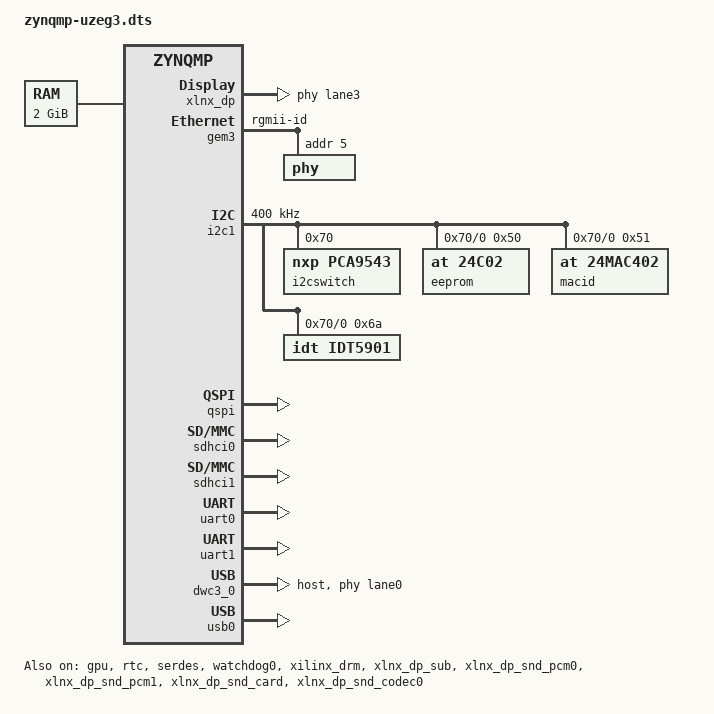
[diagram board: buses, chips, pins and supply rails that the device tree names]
/*
 * CAUTION: This file is automatically generated by Xilinx.
 * Version:
 * Today is: Wed Mar 15 10:40:02 2017
*/


/dts-v1/;
/include/ "zynqmp.dtsi"
/include/ "zynqmp-clk.dtsi"


/ {
	chosen {
		bootargs = "console=ttyPS0,115200";
	};
	aliases {
		ethernet0 = &gem3;
		serial0 = &uart0;
		serial1 = &uart1;
		spi0 = &qspi;
	};
	memory {
		device_type = "memory";
		reg = <0x0 0x0 0x0 0x80000000>;
	};
	cpus {
	};
};
&lpd_dma_chan1 {
	status = "okay";
};
&lpd_dma_chan2 {
	status = "okay";
};
&lpd_dma_chan3 {
	status = "okay";
};
&lpd_dma_chan4 {
	status = "okay";
};
&lpd_dma_chan5 {
	status = "okay";
};
&lpd_dma_chan6 {
	status = "okay";
};
&lpd_dma_chan7 {
	status = "okay";
};
&lpd_dma_chan8 {
	status = "okay";
};
&xlnx_dp {
  power-domains = <&pd_dp>;
	status = "okay";
	phy-names = "dp-phy0", "dp-phy1";
	phys = <&lane3 5 0 3 27000000>, <&lane2 5 1 3 27000000>;
	xlnx,max-lanes = <2>;
};

&xlnx_dpdma {
	status = "okay";
};

&gem3 {
	local-mac-address = [00 0a 35 00 00 00];
	phy-mode = "rgmii-id";
	status = "okay";
	xlnx,ptp-enet-clock = <0x0>;
	phy@5 {
		reg = <0x5>;
		ti,rx-internal-delay = <0x5>;
		ti,tx-internal-delay = <0x5>;
		ti,fifo-depth = <0x1>;
		linux,phandle = <0x80>;
		phandle = <0x80>;
	};
};
&fpd_dma_chan1 {
	status = "okay";
};
&fpd_dma_chan2 {
	status = "okay";
};
&fpd_dma_chan3 {
	status = "okay";
};
&fpd_dma_chan4 {
	status = "okay";
};
&fpd_dma_chan5 {
	status = "okay";
};
&fpd_dma_chan6 {
	status = "okay";
};
&fpd_dma_chan7 {
	status = "okay";
};
&fpd_dma_chan8 {
	status = "okay";
};
&gpio {
	emio-gpio-width = <32>;
	gpio-mask-high = <0x0>;
	gpio-mask-low = <0x5600>;
	status = "okay";
};

&gpu {
	status = "okay";
};

&i2c1 {
	clock-frequency = <400000>;
	status = "okay";

	i2cswitch@70 {
        	compatible = "nxp,pca9543";
       		#address-cells = <1>;
        	#size-cells = <0>;
        	reg = <0x70>;

        	i2c@0 {
        		    #address-cells = <1>;
            		#size-cells = <0>;
            		reg = <0>;

                eeprom: eeprom1@50 {
                     compatible = "at,24c02";
                     reg = <0x50>;
                };

            		macid: eeprom2@51 {
                		compatible = "at,24mac402";
                		reg = <0x51>;
			          };

                idt5901: clock-generator@6a { /* IDT 5P49V5935 clock generator - IOCC U1 */
                     #clock-cells = <0>;
                     compatible = "idt,idt5901";
                     reg = <0x6a>;
                     input-freq = <25000000>;
                     clk-freq = <75000000>;
                     output-num = <4>;
                };
        	};
          i2c@1 { /* i2c mw 70 0 2 */
                #address-cells = <1>;
                #size-cells = <0>;
                reg = <1>;
                /* SMBUS */
           };
 	    };
};
&qspi {
	is-dual = <1>;
	num-cs = <1>;
	status = "okay";
};
&rtc {
	status = "okay";
};
&sata {
	status = "disabled";
};
&sdhci0 {
	clock-frequency = <199998000>;
	status = "okay";
	xlnx,mio_bank = <0x0>;
};
&sdhci1 {
	clock-frequency = <199998000>;
	status = "okay";
	xlnx,mio_bank = <0x1>;
	no-1-8-v;
};
&serdes {
	status = "okay";
};
&uart0 {
	device_type = "serial";
	port-number = <0>;
	status = "okay";
};
&uart1 {
	device_type = "serial";
	port-number = <1>;
	status = "okay";
};
&dwc3_0 {
	dr_mode = "host";
	status = "okay";
	snps,usb3_lpm_capable;
	phy-names = "usb3-phy";
	phys = <&lane0 4 0 0 52000000>;
};
&watchdog0 {
	status = "okay";
};
&usb0 {
	status = "okay";
};

&xilinx_drm {
  power-domains = <&pd_dp>;
	status = "okay";
	clocks = <&idt5901>;
	planes {
        	xlnx,pixel-format = "argb8888";
    	};
};

&xlnx_dp_sub {
  power-domains = <&pd_dp>;
	status = "okay";
	xlnx,vid-clk-pl;
  xlnx,gfx-fmt = "argb8888";
};

&xlnx_dp_snd_pcm0 {
  power-domains = <&pd_dp>;
	status = "okay";
};

&xlnx_dp_snd_pcm1 {
  power-domains = <&pd_dp>;
	status = "okay";
};

&xlnx_dp_snd_card {
  power-domains = <&pd_dp>;
	status = "okay";
};

&xlnx_dp_snd_codec0 {
  power-domains = <&pd_dp>;
	status = "okay";
};
